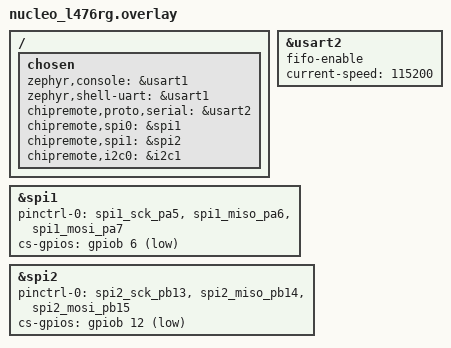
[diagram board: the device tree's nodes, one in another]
/ {
        chosen {
                zephyr,console = &usart1;
                zephyr,shell-uart = &usart1;
                chipremote,proto,serial = &usart2;
                chipremote,spi0 = &spi1;
                chipremote,spi1 = &spi2;
                chipremote,i2c0 = &i2c1;
        };
};

&usart2 {
        fifo-enable;
        current-speed = <115200>;
};

/* spi: Let's use cs-gpios instead of the peripheral's nss pin. */

&spi1 {
        status = "okay";
        pinctrl-0 = <&spi1_sck_pa5
                     &spi1_miso_pa6
                     &spi1_mosi_pa7>;
        pinctrl-names = "default";
        cs-gpios = <&gpiob 6 (GPIO_ACTIVE_LOW | GPIO_PULL_UP)>;
};

&spi2 {
        status = "okay";
        pinctrl-0 = <&spi2_sck_pb13
                     &spi2_miso_pb14
                     &spi2_mosi_pb15>;
        pinctrl-names = "default";
        cs-gpios = <&gpiob 12 (GPIO_ACTIVE_LOW | GPIO_PULL_UP)>;
};
